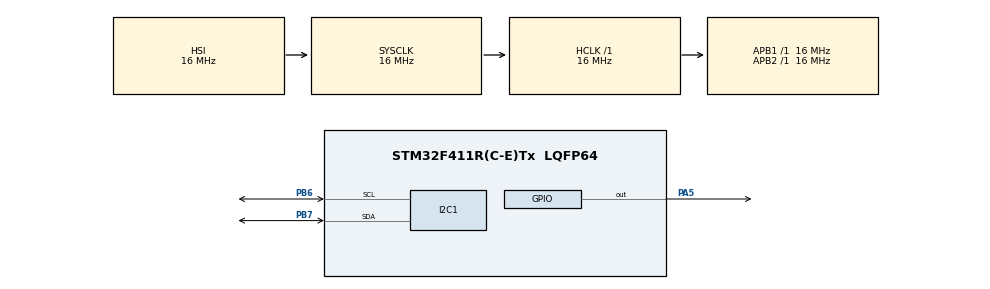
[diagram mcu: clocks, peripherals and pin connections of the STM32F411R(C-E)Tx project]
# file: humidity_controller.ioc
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FREERTOS.Tasks01=defaultTask,24,128,StartDefaultTask,Default,NULL,Dynamic,NULL,NULL
FREERTOS.configUSE_NEWLIB_REENTRANT=1
Mcu.Family=STM32F4
Mcu.Name=STM32F411R(C-E)Tx
Mcu.Package=LQFP64
NVIC.PriorityGroup=NVIC_PRIORITYGROUP_4
NVIC.TIM5_IRQn=true\:15\:0\:false\:false\:true\:false\:false\:true\:true
NVIC.TimeBase=TIM5_IRQn
NVIC.TimeBaseIP=TIM5
PA13.Mode=Serial_Wire
PA13.Signal=SYS_JTMS-SWDIO
PA14.Mode=Serial_Wire
PA14.Signal=SYS_JTCK-SWCLK
PA5.Signal=GPIO_Output
PB6.Mode=I2C
PB6.Signal=I2C1_SCL
PB7.Mode=I2C
PB7.Signal=I2C1_SDA
ProjectManager.HeapSize=0x200
ProjectManager.StackSize=0x400
ProjectManager.TargetToolchain=STM32CubeIDE
RCC.AHBFreq_Value=16000000
RCC.APB1Freq_Value=16000000
RCC.APB2Freq_Value=16000000
RCC.CortexFreq_Value=16000000
RCC.HSE_VALUE=25000000
RCC.HSI_VALUE=16000000
RCC.LSE_VALUE=32768
RCC.SYSCLKFreq_VALUE=16000000
RCC.VCOOutputFreq_Value=192000000
VP_FREERTOS_VS_CMSIS_V2.Mode=CMSIS_V2
VP_SYS_VS_tim5.Mode=TIM5
board=custom

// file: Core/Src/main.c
/* USER CODE BEGIN Header */
/**
  ******************************************************************************
  * @file           : main.c
  * @brief          : Main program body
  ******************************************************************************
  * @attention
  *
  * Copyright (c) 2026 STMicroelectronics.
  * All rights reserved.
  *
  * This software is licensed under terms that can be found in the LICENSE file
  * in the root directory of this software component.
  * If no LICENSE file comes with this software, it is provided AS-IS.
  *
  ******************************************************************************
  */
/* USER CODE END Header */
#include "main.h"
#include "cmsis_os.h"

/* USER CODE BEGIN Includes */
#include <stdbool.h>

#include "sht3x.h"

/* USER CODE END Includes */

/* USER CODE BEGIN PD */
#define ENABLE_SHT3X 1 // NOTE: Set 1 to enable SHT3X task, or 0 to disable if not using sensor

/* USER CODE END PD */

I2C_HandleTypeDef hi2c1;

/* Definitions for defaultTask */
osThreadId_t defaultTaskHandle;
const osThreadAttr_t defaultTask_attributes = {
  .name = "defaultTask",
  .stack_size = 128 * 4,
  .priority = (osPriority_t) osPriorityNormal,
};
/* USER CODE BEGIN PV */
osThreadId_t sht3xTaskHandle;
const osThreadAttr_t sht3xTask_attributes = {
  .name = "Sht3xTask",
  .stack_size = 256 * 4,
  .priority = (osPriority_t) osPriorityBelowNormal,
};

// Global variables for sharing sensor data and status with other parts of the application.
static sht3x_t sht3x_sensor;
volatile sht3x_sample_t g_sht3x_sample = {0};
volatile uint32_t g_sht3x_read_count = 0;
volatile uint32_t g_sht3x_error_count = 0;
volatile HAL_StatusTypeDef g_sht3x_last_error = HAL_OK;
volatile bool g_sht3x_sensor_ready = false;
volatile bool g_sht3x_sample_valid = false;

/* USER CODE END PV */

void SystemClock_Config(void);
static void MX_GPIO_Init(void);
static void MX_I2C1_Init(void);
void StartDefaultTask(void *argument);

/* USER CODE BEGIN PFP */
void StartSht3xTask(void *argument);

/* USER CODE END PFP */

int main(void)
{

  /* MCU Configuration--------------------------------------------------------*/

  /* Reset of all peripherals, Initializes the Flash interface and the Systick. */
  HAL_Init();

  /* Configure the system clock */
  SystemClock_Config();

  /* Initialize all configured peripherals */
  MX_GPIO_Init();
  MX_I2C1_Init();

  /* Init scheduler */
  osKernelInitialize();

  /* Create the thread(s) */
  /* creation of defaultTask */
  defaultTaskHandle = osThreadNew(StartDefaultTask, NULL, &defaultTask_attributes);

  /* USER CODE BEGIN RTOS_THREADS */
#if ENABLE_SHT3X
  sht3xTaskHandle = osThreadNew(StartSht3xTask, NULL, &sht3xTask_attributes);
#endif
  /* USER CODE END RTOS_THREADS */

  /* Start scheduler */
  osKernelStart();

  /* We should never get here as control is now taken by the scheduler */

  /* Infinite loop */
  while (1)
  {

  }
}

void SystemClock_Config(void)
{
  RCC_OscInitTypeDef RCC_OscInitStruct = {0};
  RCC_ClkInitTypeDef RCC_ClkInitStruct = {0};

  /** Configure the main internal regulator output voltage
  */
  __HAL_RCC_PWR_CLK_ENABLE();
  __HAL_PWR_VOLTAGESCALING_CONFIG(PWR_REGULATOR_VOLTAGE_SCALE1);

  /** Initializes the RCC Oscillators according to the specified parameters
  * in the RCC_OscInitTypeDef structure.
  */
  RCC_OscInitStruct.OscillatorType = RCC_OSCILLATORTYPE_HSI;
  RCC_OscInitStruct.HSIState = RCC_HSI_ON;
  RCC_OscInitStruct.HSICalibrationValue = RCC_HSICALIBRATION_DEFAULT;
  RCC_OscInitStruct.PLL.PLLState = RCC_PLL_NONE;
  if (HAL_RCC_OscConfig(&RCC_OscInitStruct) != HAL_OK)
  {
    Error_Handler();
  }

  /** Initializes the CPU, AHB and APB buses clocks
  */
  RCC_ClkInitStruct.ClockType = RCC_CLOCKTYPE_HCLK|RCC_CLOCKTYPE_SYSCLK
                              |RCC_CLOCKTYPE_PCLK1|RCC_CLOCKTYPE_PCLK2;
  RCC_ClkInitStruct.SYSCLKSource = RCC_SYSCLKSOURCE_HSI;
  RCC_ClkInitStruct.AHBCLKDivider = RCC_SYSCLK_DIV1;
  RCC_ClkInitStruct.APB1CLKDivider = RCC_HCLK_DIV1;
  RCC_ClkInitStruct.APB2CLKDivider = RCC_HCLK_DIV1;

  if (HAL_RCC_ClockConfig(&RCC_ClkInitStruct, FLASH_LATENCY_0) != HAL_OK)
  {
    Error_Handler();
  }
}

static void MX_I2C1_Init(void)
{

  hi2c1.Instance = I2C1;
  hi2c1.Init.ClockSpeed = 100000;
  hi2c1.Init.DutyCycle = I2C_DUTYCYCLE_2;
  hi2c1.Init.OwnAddress1 = 0;
  hi2c1.Init.AddressingMode = I2C_ADDRESSINGMODE_7BIT;
  hi2c1.Init.DualAddressMode = I2C_DUALADDRESS_DISABLE;
  hi2c1.Init.OwnAddress2 = 0;
  hi2c1.Init.GeneralCallMode = I2C_GENERALCALL_DISABLE;
  hi2c1.Init.NoStretchMode = I2C_NOSTRETCH_DISABLE;
  if (HAL_I2C_Init(&hi2c1) != HAL_OK)
  {
    Error_Handler();
  }

}

static void MX_GPIO_Init(void)
{

  /* GPIO Ports Clock Enable */
  __HAL_RCC_GPIOA_CLK_ENABLE();
  __HAL_RCC_GPIOB_CLK_ENABLE();

}

/* USER CODE BEGIN 4 */
#define SHT3X_I2C_ADDRESS                0x44U // from table 8 of SHT3x datasheet, this is the default address when ADDR pin is low.
#define SHT3X_TASK_PERIOD_MS             5000U // poll the sensor every 5 seconds, which is a reasonable interval for monitoring temperature and humidity in a typical environment without consuming too much power or I2C bus bandwidth.
#define SHT3X_TASK_RETRY_DELAY_MS         500U

void StartSht3xTask(void *argument)
{
  (void)argument;

#if ENABLE_SHT3X
  sht3x_sample_t sample;

  for(;;)
  {
    if (!sht3x_sensor.initialized)
    {
      g_sht3x_sensor_ready = sht3x_init(&sht3x_sensor, &hi2c1, SHT3X_I2C_ADDRESS);
      g_sht3x_last_error = sht3x_sensor.last_error;

      if (!g_sht3x_sensor_ready)
      {
        g_sht3x_sample_valid = false;
        g_sht3x_error_count++;
        osDelay(SHT3X_TASK_RETRY_DELAY_MS);
        continue;
      }
    }

    if (sht3x_read(&sht3x_sensor, &sample))
    {
      g_sht3x_sample = sample;
      g_sht3x_last_error = HAL_OK;
      g_sht3x_sensor_ready = true;
      g_sht3x_sample_valid = true;
      g_sht3x_read_count++;
    }
    else
    {
      g_sht3x_last_error = sht3x_sensor.last_error;
      g_sht3x_sensor_ready = false;
      g_sht3x_sample_valid = false;
      g_sht3x_error_count++;
    }

    osDelay(SHT3X_TASK_PERIOD_MS);
  }
#else
  for(;;)
  {
    osDelay(1000);
  }
#endif
}

/* USER CODE END 4 */

void StartDefaultTask(void *argument)
{
  for(;;)
  {
    osDelay(1);
  }
}

void HAL_TIM_PeriodElapsedCallback(TIM_HandleTypeDef *htim)
{
  if (htim->Instance == TIM5)
  {
    HAL_IncTick();
  }
}

void Error_Handler(void)
{
  __disable_irq();
  while (1)
  {
  }
}
